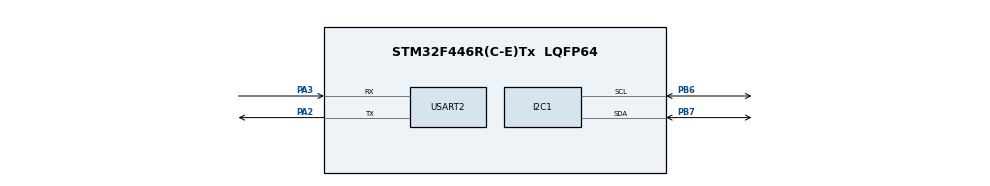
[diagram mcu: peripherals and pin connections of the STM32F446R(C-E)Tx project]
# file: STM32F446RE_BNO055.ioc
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I2C1.I2C_Mode=I2C_Fast
Mcu.Family=STM32F4
Mcu.Name=STM32F446R(C-E)Tx
Mcu.Package=LQFP64
NVIC.PriorityGroup=NVIC_PRIORITYGROUP_4
PA13.Mode=Serial_Wire
PA13.Signal=SYS_JTMS-SWDIO
PA14.Mode=Serial_Wire
PA14.Signal=SYS_JTCK-SWCLK
PA2.Mode=Asynchronous
PA2.Signal=USART2_TX
PA3.Mode=Asynchronous
PA3.Signal=USART2_RX
PB6.Mode=I2C
PB6.Signal=I2C1_SCL
PB7.Mode=I2C
PB7.Signal=I2C1_SDA
ProjectManager.HeapSize=0x200
ProjectManager.StackSize=0x400
ProjectManager.TargetToolchain=STM32CubeIDE
RCC.CortexFreq_Value=16000000
RCC.USBFreq_Value=96000000
RCC.VCOOutputFreq_Value=192000000
USART2.VirtualMode=VM_ASYNC
board=custom

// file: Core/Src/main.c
/* USER CODE BEGIN Header */
/**
  ******************************************************************************
  * @file           : main.c
  * @brief          : Main program body
  ******************************************************************************
  * @attention
  *
  * <h2><center>&copy; Copyright (c) 2022 STMicroelectronics.
  * All rights reserved.</center></h2>
  *
  * This software component is licensed by ST under BSD 3-Clause license,
  * the "License"; You may not use this file except in compliance with the
  * License. You may obtain a copy of the License at:
  *                        opensource.org/licenses/BSD-3-Clause
  *
  ******************************************************************************
  */

//DIKKAT DIKKAT! BU KOD DENENMEMIS CALISMAMASI MUHTEMEL BIR KODDUR.

/* USER CODE END Header */
#include "main.h"
#include "i2c.h"
#include "usart.h"
#include "gpio.h"

/* USER CODE BEGIN Includes */
#include "bno055_stm32.h"
#include <string.h>
/* USER CODE END Includes */

void SystemClock_Config(void);

int main(void)
{

  /* MCU Configuration--------------------------------------------------------*/

  /* Reset of all peripherals, Initializes the Flash interface and the Systick. */
  HAL_Init();

  /* Configure the system clock */
  SystemClock_Config();

  /* Initialize all configured peripherals */
  MX_GPIO_Init();
  MX_I2C1_Init();
  MX_USART2_UART_Init();
  /* USER CODE BEGIN 2 */
  bno055_assignI2C(&hi2c1);
  bno055_setup();
  bno055_setOperationModeNDOF();
  /* USER CODE END 2 */

  /* Infinite loop */
  /* USER CODE BEGIN WHILE */
  while (1)
  {

		/*
	  bno055_vector_t v = bno055_getVectorEuler();
	  printf("Heading: %.2f Roll: %.2f Pitch: %.2f\r\n", v.x, v.y, v.z);
	  HAL_Delay(1000);
		 */

	    bno055_vector_t v = bno055_getVectorEuler();
		char buffer[100];
		sprintf(buffer, "Heading: %.2f Roll: %.2f Pitch: %.2f\r\n", v.x, v.y, v.z);
		HAL_UART_Transmit(&huart2, buffer, strlen(buffer), 1000);

    /* USER CODE END WHILE */

  }
}

void SystemClock_Config(void)
{
  RCC_OscInitTypeDef RCC_OscInitStruct = {0};
  RCC_ClkInitTypeDef RCC_ClkInitStruct = {0};

  /** Configure the main internal regulator output voltage
  */
  __HAL_RCC_PWR_CLK_ENABLE();
  __HAL_PWR_VOLTAGESCALING_CONFIG(PWR_REGULATOR_VOLTAGE_SCALE3);
  /** Initializes the RCC Oscillators according to the specified parameters
  * in the RCC_OscInitTypeDef structure.
  */
  RCC_OscInitStruct.OscillatorType = RCC_OSCILLATORTYPE_HSI;
  RCC_OscInitStruct.HSIState = RCC_HSI_ON;
  RCC_OscInitStruct.HSICalibrationValue = RCC_HSICALIBRATION_DEFAULT;
  RCC_OscInitStruct.PLL.PLLState = RCC_PLL_NONE;
  if (HAL_RCC_OscConfig(&RCC_OscInitStruct) != HAL_OK)
  {
    Error_Handler();
  }
  /** Initializes the CPU, AHB and APB buses clocks
  */
  RCC_ClkInitStruct.ClockType = RCC_CLOCKTYPE_HCLK|RCC_CLOCKTYPE_SYSCLK
                              |RCC_CLOCKTYPE_PCLK1|RCC_CLOCKTYPE_PCLK2;
  RCC_ClkInitStruct.SYSCLKSource = RCC_SYSCLKSOURCE_HSI;
  RCC_ClkInitStruct.AHBCLKDivider = RCC_SYSCLK_DIV1;
  RCC_ClkInitStruct.APB1CLKDivider = RCC_HCLK_DIV1;
  RCC_ClkInitStruct.APB2CLKDivider = RCC_HCLK_DIV1;

  if (HAL_RCC_ClockConfig(&RCC_ClkInitStruct, FLASH_LATENCY_0) != HAL_OK)
  {
    Error_Handler();
  }
}

void Error_Handler(void)
{
  __disable_irq();
  while (1)
  {
  }
}

/************************ (C) COPYRIGHT STMicroelectronics *****END OF FILE****/
